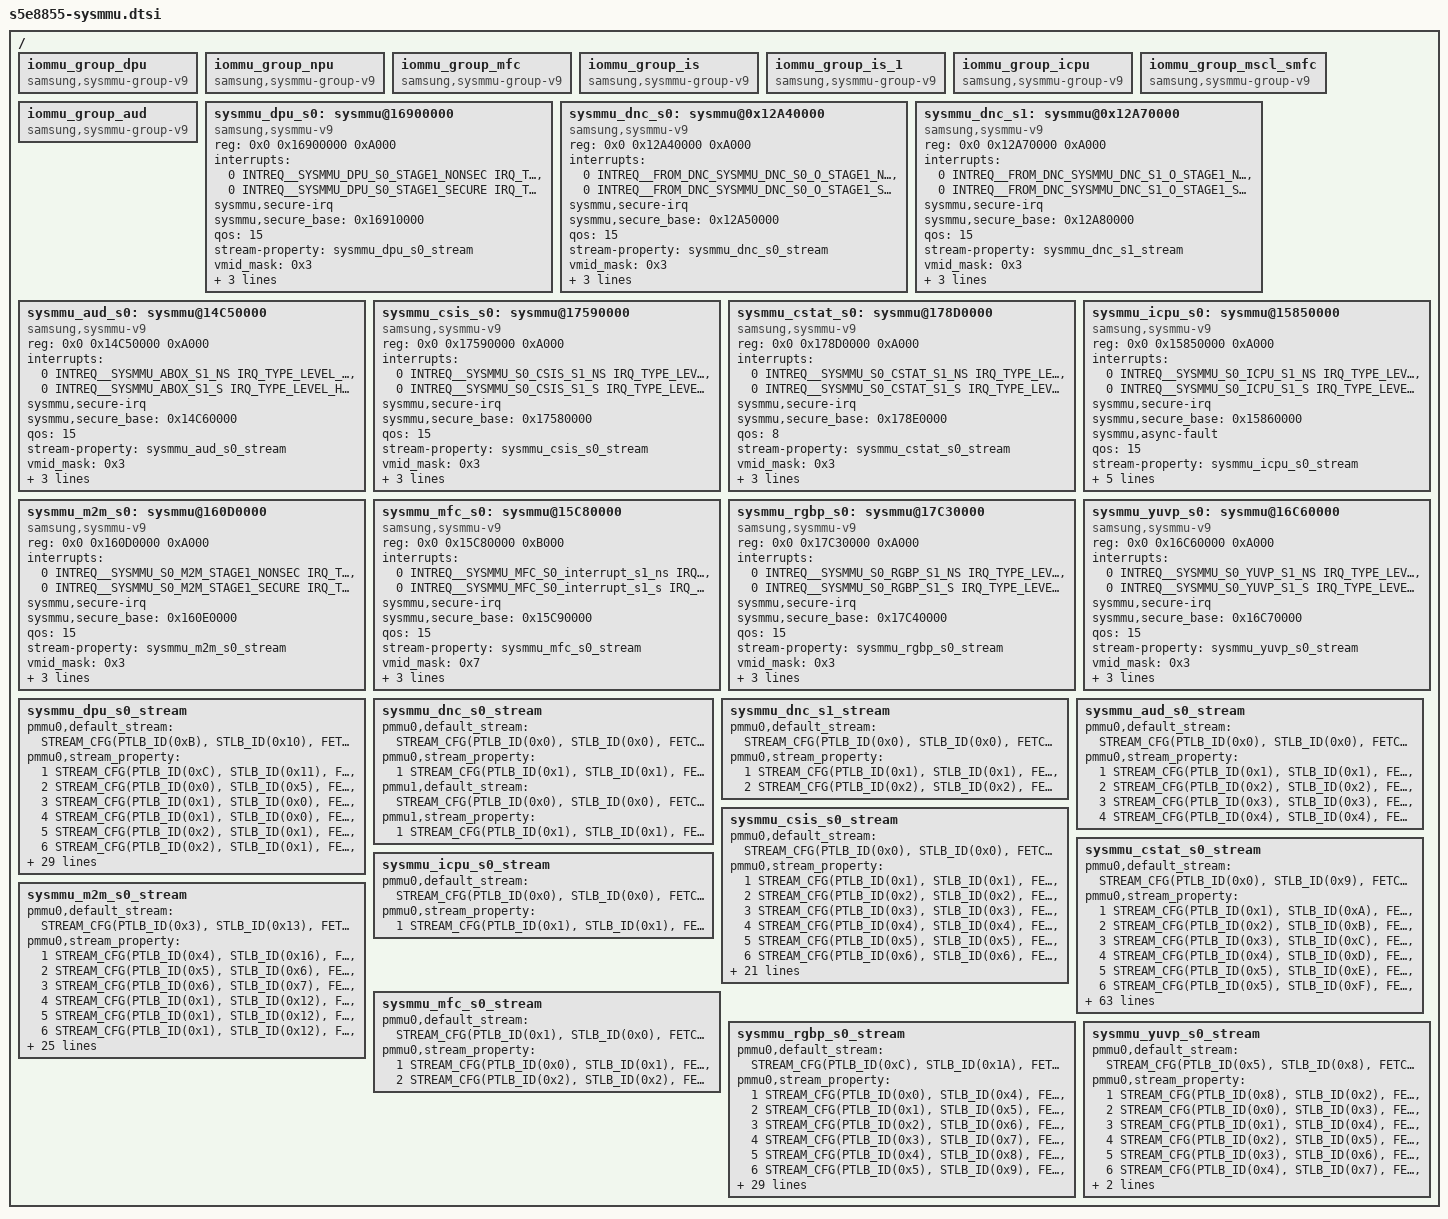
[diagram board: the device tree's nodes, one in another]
// SPDX-License-Identifier: GPL-2.0
/*
 * SAMSUNG S5E8855 SoC device tree source
 *
 * Copyright (c) 2023 Samsung Electronics Co., Ltd.
 *      http://www.samsung.com
 *
 * SAMSUNG S5E8855 SoC device nodes are listed in this file.
 * S5E8855 based board files can include this file and provide
 * values for board specific bindings.
 *
 * This program is free software; you can redistribute it and/or modify
 * it under the terms of the GNU General Public License version 2 as
 * published by the Free Software Foundation.
 */

#include <dt-bindings/interrupt-controller/arm-gic.h>
#include <dt-bindings/soc/samsung,sysmmu-v9.h>

/ {
	iommu_group_dpu: iommu_group_dpu {
		compatible = "samsung,sysmmu-group-v9";
	};

	iommu_group_npu: iommu_group_npu {
		compatible = "samsung,sysmmu-group-v9";
	};

	iommu_group_mfc: iommu_group_mfc {
		compatible = "samsung,sysmmu-group-v9";
	};

	iommu_group_is: iommu_group_is {
		compatible = "samsung,sysmmu-group-v9";
	};

	iommu_group_is_1: iommu_group_is_1 {
		compatible = "samsung,sysmmu-group-v9";
	};

	iommu_group_icpu: iommu_group_icpu {
		compatible = "samsung,sysmmu-group-v9";
	};

	iommu_group_mscl_smfc: iommu_group_mscl_smfc {
		compatible = "samsung,sysmmu-group-v9";
	};

	iommu_group_aud: iommu_group_aud {
		compatible = "samsung,sysmmu-group-v9";
	};

	sysmmu_dpu_s0: sysmmu@16900000 {
		compatible = "samsung,sysmmu-v9";
		reg = <0x0 0x16900000 0xA000>;
		interrupts = <0 INTREQ__SYSMMU_DPU_S0_STAGE1_NONSEC IRQ_TYPE_LEVEL_HIGH>,
				<0 INTREQ__SYSMMU_DPU_S0_STAGE1_SECURE IRQ_TYPE_LEVEL_HIGH>;
		sysmmu,secure-irq;
		sysmmu,secure_base = <0x16910000>;
		qos = <15>;
		#iommu-cells = <0>;
		stream-property = <&sysmmu_dpu_s0_stream>;
		vmid_mask = <0x3>;
		sysmmu,feature-info = <0x1>;
		port-name = "DPU_DMA_TOP";
		power-domains = <&pd_dpu>;
	};

	sysmmu_dnc_s0: sysmmu@0x12A40000 {
		compatible = "samsung,sysmmu-v9";
		reg = <0x0 0x12A40000 0xA000>;
		interrupts = <0 INTREQ__FROM_DNC_SYSMMU_DNC_S0_O_STAGE1_NONSEC IRQ_TYPE_LEVEL_HIGH>,
				<0 INTREQ__FROM_DNC_SYSMMU_DNC_S0_O_STAGE1_SECURE IRQ_TYPE_LEVEL_HIGH>;
		sysmmu,secure-irq;
		sysmmu,secure_base = <0x12A50000>;
		qos = <15>;
		#iommu-cells = <0>;
		stream-property = <&sysmmu_dnc_s0_stream>;
		vmid_mask = <0x3>;
		sysmmu,feature-info = <0x1>;
		power-domains = <&pd_dnc>;
		port-name = "DNC S0";
	};

	sysmmu_dnc_s1: sysmmu@0x12A70000 {
		compatible = "samsung,sysmmu-v9";
		reg = <0x0 0x12A70000 0xA000>;
		interrupts = <0 INTREQ__FROM_DNC_SYSMMU_DNC_S1_O_STAGE1_NONSEC IRQ_TYPE_LEVEL_HIGH>,
				<0 INTREQ__FROM_DNC_SYSMMU_DNC_S1_O_STAGE1_SECURE IRQ_TYPE_LEVEL_HIGH>;
		sysmmu,secure-irq;
		sysmmu,secure_base = <0x12A80000>;
		qos = <15>;
		#iommu-cells = <0>;
		stream-property = <&sysmmu_dnc_s1_stream>;
		vmid_mask = <0x3>;
		sysmmu,feature-info = <0x1>;
		power-domains = <&pd_dnc>;
		port-name = "DNC S1";
	};

	sysmmu_aud_s0: sysmmu@14C50000 {
		compatible = "samsung,sysmmu-v9";
		reg = <0x0 0x14C50000 0xA000>;
		interrupts = <0 INTREQ__SYSMMU_ABOX_S1_NS IRQ_TYPE_LEVEL_HIGH>,
				<0 INTREQ__SYSMMU_ABOX_S1_S IRQ_TYPE_LEVEL_HIGH>;
		sysmmu,secure-irq;
		sysmmu,secure_base = <0x14C60000>;
		qos = <15>;
		#iommu-cells = <0>;
		stream-property = <&sysmmu_aud_s0_stream>;
		vmid_mask = <0x3>;
		sysmmu,feature-info = <0x1>;
		port-name = "ABOX (CA32_0) ABOX (CA32_1) ...";
		power-domains = <&pd_aud>;
	};

	sysmmu_csis_s0: sysmmu@17590000 {
		compatible = "samsung,sysmmu-v9";
		reg = <0x0 0x17590000 0xA000>;
		interrupts = <0 INTREQ__SYSMMU_S0_CSIS_S1_NS IRQ_TYPE_LEVEL_HIGH>,
				<0 INTREQ__SYSMMU_S0_CSIS_S1_S IRQ_TYPE_LEVEL_HIGH>;
		sysmmu,secure-irq;
		sysmmu,secure_base = <0x17580000>;
		qos = <15>;
		#iommu-cells = <0>;
		stream-property = <&sysmmu_csis_s0_stream>;
		vmid_mask = <0x3>;
		sysmmu,feature-info = <0x1>;
		port-name = "CSIS DMA0-3, PDP_M0 ...";
		power-domains = <&pd_csis>;
	};

	sysmmu_cstat_s0: sysmmu@178D0000 {
		compatible = "samsung,sysmmu-v9";
		reg = <0x0 0x178D0000 0xA000>;
		interrupts = <0 INTREQ__SYSMMU_S0_CSTAT_S1_NS IRQ_TYPE_LEVEL_HIGH>,
				<0 INTREQ__SYSMMU_S0_CSTAT_S1_S IRQ_TYPE_LEVEL_HIGH>;
		sysmmu,secure-irq;
		sysmmu,secure_base = <0x178E0000>;
		qos = <8>;
		#iommu-cells = <0>;
		stream-property = <&sysmmu_cstat_s0_stream>;
		vmid_mask = <0x3>;
		sysmmu,feature-info = <0x1>;
		port-name = "CSTAT, BYRP, MCSC ...";
		power-domains = <&pd_cstat>;
	};

	sysmmu_icpu_s0: sysmmu@15850000 {
		compatible = "samsung,sysmmu-v9";
		reg = <0x0 0x15850000 0xA000>;
		interrupts = <0 INTREQ__SYSMMU_S0_ICPU_S1_NS IRQ_TYPE_LEVEL_HIGH>,
				<0 INTREQ__SYSMMU_S0_ICPU_S1_S  IRQ_TYPE_LEVEL_HIGH>;
		sysmmu,secure-irq;
		sysmmu,secure_base = <0x15860000>;
		sysmmu,async-fault;
		qos = <15>;
		#iommu-cells = <0>;
		stream-property = <&sysmmu_icpu_s0_stream>;
		vmid_mask = <0x3>;
		sysmmu,feature-info = <0x1>;
		sysmmu,cacheable-override;
		port-name = "ICPU";
		power-domains = <&pd_icpu>;
	};

	sysmmu_m2m_s0: sysmmu@160D0000 {
		compatible = "samsung,sysmmu-v9";
		reg = <0x0 0x160D0000 0xA000>;
		interrupts = <0 INTREQ__SYSMMU_S0_M2M_STAGE1_NONSEC IRQ_TYPE_LEVEL_HIGH>,
				<0 INTREQ__SYSMMU_S0_M2M_STAGE1_SECURE IRQ_TYPE_LEVEL_HIGH>;
		sysmmu,secure-irq;
		sysmmu,secure_base = <0x160E0000>;
		qos = <15>;
		#iommu-cells = <0>;
		stream-property = <&sysmmu_m2m_s0_stream>;
		vmid_mask = <0x3>;
		sysmmu,feature-info = <0x1>;
		port-name = "M2M, SMFC, GDC ...";
		power-domains = <&pd_m2m>;
	};

	sysmmu_mfc_s0: sysmmu@15C80000 {
		compatible = "samsung,sysmmu-v9";
		reg = <0x0 0x15C80000 0xB000>;
		interrupts = <0 INTREQ__SYSMMU_MFC_S0_interrupt_s1_ns IRQ_TYPE_LEVEL_HIGH>,
				<0 INTREQ__SYSMMU_MFC_S0_interrupt_s1_s IRQ_TYPE_LEVEL_HIGH>;
		sysmmu,secure-irq;
		sysmmu,secure_base = <0x15C90000>;
		qos = <15>;
		#iommu-cells = <0>;
		stream-property = <&sysmmu_mfc_s0_stream>;
		vmid_mask = <0x7>;
		sysmmu,feature-info = <0x1>;
		port-name = "MFC0";
		power-domains = <&pd_mfc>;
	};

	sysmmu_rgbp_s0: sysmmu@17C30000 {
		compatible = "samsung,sysmmu-v9";
		reg = <0x0 0x17C30000 0xA000>;
		interrupts = <0 INTREQ__SYSMMU_S0_RGBP_S1_NS IRQ_TYPE_LEVEL_HIGH>,
				<0 INTREQ__SYSMMU_S0_RGBP_S1_S IRQ_TYPE_LEVEL_HIGH>;
		sysmmu,secure-irq;
		sysmmu,secure_base = <0x17C40000>;
		qos = <15>;
		#iommu-cells = <0>;
		stream-property = <&sysmmu_rgbp_s0_stream>;
		vmid_mask = <0x3>;
		sysmmu,feature-info = <0x1>;
		port-name = "RGBP, MCFP ...";
		power-domains = <&pd_rgbp>;
	};

	sysmmu_yuvp_s0: sysmmu@16C60000 {
		compatible = "samsung,sysmmu-v9";
		reg = <0x0 0x16C60000 0xA000>;
		interrupts = <0 INTREQ__SYSMMU_S0_YUVP_S1_NS IRQ_TYPE_LEVEL_HIGH>,
				<0 INTREQ__SYSMMU_S0_YUVP_S1_S IRQ_TYPE_LEVEL_HIGH>;
		sysmmu,secure-irq;
		sysmmu,secure_base = <0x16C70000>;
		qos = <15>;
		#iommu-cells = <0>;
		stream-property = <&sysmmu_yuvp_s0_stream>;
		vmid_mask = <0x3>;
		sysmmu,feature-info = <0x1>;
		port-name = "YUVP";
		power-domains = <&pd_yuvp>;
	};

	sysmmu_dpu_s0_stream: sysmmu_dpu_s0_stream {
		pmmu0,default_stream =
		<STREAM_CFG(PTLB_ID(0xB), STLB_ID(0x10), FETCH_SIZE(SIZE1), PTLB_EN, STLB_EN)>;
		pmmu0,stream_property =
		<1 STREAM_CFG(PTLB_ID(0xC), STLB_ID(0x11), FETCH_SIZE(SIZE1), PTLB_EN, STLB_EN)
		 STREAM_MATCH_CFG(DIR_READ)
		 STREAM_MATCH_SID_VALUE(0x1A)
		 STREAM_MATCH_SID_MASK(0xFF)>,
		<2 STREAM_CFG(PTLB_ID(0x0), STLB_ID(0x5), FETCH_SIZE(SIZE2), PTLB_EN, STLB_EN)
		 STREAM_MATCH_CFG(DIR_READ)
		 STREAM_MATCH_SID_VALUE(0x0)
		 STREAM_MATCH_SID_MASK(0xFF)>,
		<3 STREAM_CFG(PTLB_ID(0x1), STLB_ID(0x0), FETCH_SIZE(SIZE32), PTLB_DIS, STLB_EN)
		 STREAM_MATCH_CFG(DIR_READ)
		 STREAM_MATCH_SID_VALUE(0x4)
		 STREAM_MATCH_SID_MASK(0xFF)>,
		<4 STREAM_CFG(PTLB_ID(0x1), STLB_ID(0x0), FETCH_SIZE(SIZE32), PTLB_DIS, STLB_EN)
		 STREAM_MATCH_CFG(DIR_READ)
		 STREAM_MATCH_SID_VALUE(0x14)
		 STREAM_MATCH_SID_MASK(0xFF)>,
		<5 STREAM_CFG(PTLB_ID(0x2), STLB_ID(0x1), FETCH_SIZE(SIZE32), PTLB_DIS, STLB_EN)
		 STREAM_MATCH_CFG(DIR_READ)
		 STREAM_MATCH_SID_VALUE(0x5)
		 STREAM_MATCH_SID_MASK(0xFF)>,
		<6 STREAM_CFG(PTLB_ID(0x2), STLB_ID(0x1), FETCH_SIZE(SIZE32), PTLB_DIS, STLB_EN)
		 STREAM_MATCH_CFG(DIR_READ)
		 STREAM_MATCH_SID_VALUE(0x15)
		 STREAM_MATCH_SID_MASK(0xFF)>,
		<7 STREAM_CFG(PTLB_ID(0x3), STLB_ID(0x6), FETCH_SIZE(SIZE2), PTLB_EN, STLB_EN)
		 STREAM_MATCH_CFG(DIR_READ)
		 STREAM_MATCH_SID_VALUE(0x6)
		 STREAM_MATCH_SID_MASK(0xFF)>,
		<8 STREAM_CFG(PTLB_ID(0x4), STLB_ID(0x12), FETCH_SIZE(SIZE1), PTLB_EN, STLB_EN)
		 STREAM_MATCH_CFG(DIR_READ)
		 STREAM_MATCH_SID_VALUE(0x7)
		 STREAM_MATCH_SID_MASK(0xFF)>,
		<9 STREAM_CFG(PTLB_ID(0x5), STLB_ID(0x2), FETCH_SIZE(SIZE16), PTLB_EN, STLB_EN)
		 STREAM_MATCH_CFG(DIR_READ)
		 STREAM_MATCH_SID_VALUE(0x8)
		 STREAM_MATCH_SID_MASK(0xFF)>,
		<10 STREAM_CFG(PTLB_ID(0x5), STLB_ID(0x2), FETCH_SIZE(SIZE16), PTLB_EN, STLB_EN)
		 STREAM_MATCH_CFG(DIR_READ)
		 STREAM_MATCH_SID_VALUE(0x18)
		 STREAM_MATCH_SID_MASK(0xFF)>,
		<11 STREAM_CFG(PTLB_ID(0x6), STLB_ID(0x7), FETCH_SIZE(SIZE2), PTLB_EN, STLB_EN)
		 STREAM_MATCH_CFG(DIR_READ)
		 STREAM_MATCH_SID_VALUE(0xA)
		 STREAM_MATCH_SID_MASK(0xFF)>,
		<12 STREAM_CFG(PTLB_ID(0x7), STLB_ID(0x8), FETCH_SIZE(SIZE2), PTLB_EN, STLB_EN)
		 STREAM_MATCH_CFG(DIR_READ)
		 STREAM_MATCH_SID_VALUE(0xC)
		 STREAM_MATCH_SID_MASK(0xFF)>,
		<13 STREAM_CFG(PTLB_ID(0x7), STLB_ID(0x8), FETCH_SIZE(SIZE2), PTLB_EN, STLB_EN)
		 STREAM_MATCH_CFG(DIR_READ)
		 STREAM_MATCH_SID_VALUE(0x1C)
		 STREAM_MATCH_SID_MASK(0xFF)>,
		<14 STREAM_CFG(PTLB_ID(0x8), STLB_ID(0x9), FETCH_SIZE(SIZE2), PTLB_EN, STLB_EN)
		 STREAM_MATCH_CFG(DIR_READ)
		 STREAM_MATCH_SID_VALUE(0xD)
		 STREAM_MATCH_SID_MASK(0xFF)>,
		<15 STREAM_CFG(PTLB_ID(0x8), STLB_ID(0x9), FETCH_SIZE(SIZE2), PTLB_EN, STLB_EN)
		 STREAM_MATCH_CFG(DIR_READ)
		 STREAM_MATCH_SID_VALUE(0x1D)
		 STREAM_MATCH_SID_MASK(0xFF)>,
		<16 STREAM_CFG(PTLB_ID(0x9), STLB_ID(0x13), FETCH_SIZE(SIZE1), PTLB_EN, STLB_EN)
		 STREAM_MATCH_CFG(DIR_READ)
		 STREAM_MATCH_SID_VALUE(0xE)
		 STREAM_MATCH_SID_MASK(0xFF)>,
		<17 STREAM_CFG(PTLB_ID(0xA), STLB_ID(0x14), FETCH_SIZE(SIZE1), PTLB_EN, STLB_EN)
		 STREAM_MATCH_CFG(DIR_READ)
		 STREAM_MATCH_SID_VALUE(0xF)
		 STREAM_MATCH_SID_MASK(0xFF)>;
		pmmu1,default_stream =
		<STREAM_CFG(PTLB_ID(0x0), STLB_ID(0x19), FETCH_SIZE(SIZE1), PTLB_EN, STLB_EN)>;
		pmmu1,stream_property =
		<1 STREAM_CFG(PTLB_ID(0x1), STLB_ID(0x3), FETCH_SIZE(SIZE16), PTLB_EN, STLB_EN)
		 STREAM_MATCH_CFG(DIR_READ)
		 STREAM_MATCH_SID_VALUE(0x80)
		 STREAM_MATCH_SID_MASK(0xFF)>,
		<2 STREAM_CFG(PTLB_ID(0x1), STLB_ID(0x3), FETCH_SIZE(SIZE16), PTLB_EN, STLB_EN)
		 STREAM_MATCH_CFG(DIR_READ)
		 STREAM_MATCH_SID_VALUE(0x90)
		 STREAM_MATCH_SID_MASK(0xFF)>,
		<3 STREAM_CFG(PTLB_ID(0x2), STLB_ID(0xA), FETCH_SIZE(SIZE2), PTLB_EN, STLB_EN)
		 STREAM_MATCH_CFG(DIR_READ)
		 STREAM_MATCH_SID_VALUE(0x82)
		 STREAM_MATCH_SID_MASK(0xFF)>,
		<4 STREAM_CFG(PTLB_ID(0x3), STLB_ID(0xB), FETCH_SIZE(SIZE2), PTLB_EN, STLB_EN)
		 STREAM_MATCH_CFG(DIR_READ)
		 STREAM_MATCH_SID_VALUE(0x84)
		 STREAM_MATCH_SID_MASK(0xFF)>,
		<5 STREAM_CFG(PTLB_ID(0x4), STLB_ID(0xC), FETCH_SIZE(SIZE1), PTLB_EN, STLB_EN)
		 STREAM_MATCH_CFG(DIR_READ)
		 STREAM_MATCH_SID_VALUE(0x85)
		 STREAM_MATCH_SID_MASK(0xFF)>,
		<6 STREAM_CFG(PTLB_ID(0x5), STLB_ID(0xD), FETCH_SIZE(SIZE1), PTLB_EN, STLB_EN)
		 STREAM_MATCH_CFG(DIR_READ)
		 STREAM_MATCH_SID_VALUE(0x88)
		 STREAM_MATCH_SID_MASK(0xFF)>,
		<7 STREAM_CFG(PTLB_ID(0x6), STLB_ID(0x4), FETCH_SIZE(SIZE16), PTLB_EN, STLB_EN)
		 STREAM_MATCH_CFG(DIR_READ)
		 STREAM_MATCH_SID_VALUE(0x8C)
		 STREAM_MATCH_SID_MASK(0xFF)>,
		<8 STREAM_CFG(PTLB_ID(0x7), STLB_ID(0x4), FETCH_SIZE(SIZE16), PTLB_EN, STLB_EN)
		 STREAM_MATCH_CFG(DIR_READ)
		 STREAM_MATCH_SID_VALUE(0x9C)
		 STREAM_MATCH_SID_MASK(0xFF)>,
		<9 STREAM_CFG(PTLB_ID(0x7), STLB_ID(0xE), FETCH_SIZE(SIZE2), PTLB_EN, STLB_EN)
		 STREAM_MATCH_CFG(DIR_READ)
		 STREAM_MATCH_SID_VALUE(0x8D)
		 STREAM_MATCH_SID_MASK(0xFF)>,
		<10 STREAM_CFG(PTLB_ID(0x8), STLB_ID(0xE), FETCH_SIZE(SIZE2), PTLB_EN, STLB_EN)
		 STREAM_MATCH_CFG(DIR_READ)
		 STREAM_MATCH_SID_VALUE(0x9D)
		 STREAM_MATCH_SID_MASK(0xFF)>,
		<11 STREAM_CFG(PTLB_ID(0x8), STLB_ID(0xF), FETCH_SIZE(SIZE1), PTLB_EN, STLB_EN)
		 STREAM_MATCH_CFG(DIR_READ)
		 STREAM_MATCH_SID_VALUE(0x8E)
		 STREAM_MATCH_SID_MASK(0xFF)>,
		<12 STREAM_CFG(PTLB_ID(0x9), STLB_ID(0x15), FETCH_SIZE(SIZE1), PTLB_EN, STLB_EN)
		 STREAM_MATCH_CFG(DIR_READ)
		 STREAM_MATCH_SID_VALUE(0x8F)
		 STREAM_MATCH_SID_MASK(0xFF)>,
		<13 STREAM_CFG(PTLB_ID(0xA), STLB_ID(0x16), FETCH_SIZE(SIZE1), PTLB_EN, STLB_EN)
		 STREAM_MATCH_CFG(DIR_WRITE)
		 STREAM_MATCH_SID_VALUE(0x80)
		 STREAM_MATCH_SID_MASK(0xFF)>,
		<14 STREAM_CFG(PTLB_ID(0xB), STLB_ID(0x17), FETCH_SIZE(SIZE1), PTLB_EN, STLB_EN)
		 STREAM_MATCH_CFG(DIR_WRITE)
		 STREAM_MATCH_SID_VALUE(0x81)
		 STREAM_MATCH_SID_MASK(0xFF)>,
		<15 STREAM_CFG(PTLB_ID(0xC), STLB_ID(0x18), FETCH_SIZE(SIZE1), PTLB_EN, STLB_DIS)
		 STREAM_MATCH_CFG(DIR_WRITE)
		 STREAM_MATCH_SID_VALUE(0x88)
		 STREAM_MATCH_SID_MASK(0xFF)>;
	};

	sysmmu_dnc_s0_stream: sysmmu_dnc_s0_stream {
		pmmu0,default_stream =
		<STREAM_CFG(PTLB_ID(0x0), STLB_ID(0x0), FETCH_SIZE(SIZE8), PTLB_EN, STLB_EN)>;
		pmmu0,stream_property =
		<1 STREAM_CFG(PTLB_ID(0x1), STLB_ID(0x1), FETCH_SIZE(SIZE1), PTLB_DIS, STLB_DIS)
		 STREAM_MATCH_CFG(DIR_RW)
		 STREAM_MATCH_SID_VALUE(0x20)
		 STREAM_MATCH_SID_MASK(0xA0)>;
		pmmu1,default_stream =
		<STREAM_CFG(PTLB_ID(0x0), STLB_ID(0x0), FETCH_SIZE(SIZE8), PTLB_EN, STLB_EN)>;
		pmmu1,stream_property =
		<1 STREAM_CFG(PTLB_ID(0x1), STLB_ID(0x1), FETCH_SIZE(SIZE1), PTLB_DIS, STLB_DIS)
		 STREAM_MATCH_CFG(DIR_RW)
		 STREAM_MATCH_SID_VALUE(0xA0)
		 STREAM_MATCH_SID_MASK(0xA0)>;
	};

	sysmmu_dnc_s1_stream: sysmmu_dnc_s1_stream {
		pmmu0,default_stream =
		<STREAM_CFG(PTLB_ID(0x0), STLB_ID(0x0), FETCH_SIZE(SIZE1), PTLB_DIS, STLB_DIS)>;
		pmmu0,stream_property =
		<1 STREAM_CFG(PTLB_ID(0x1), STLB_ID(0x1), FETCH_SIZE(SIZE1), PTLB_DIS, STLB_EN)
		 STREAM_MATCH_CFG(DIR_READ)
		 STREAM_MATCH_SID_VALUE(0x101)
		 STREAM_MATCH_SID_MASK(0x1FF)>,
		<2 STREAM_CFG(PTLB_ID(0x2), STLB_ID(0x2), FETCH_SIZE(SIZE1), PTLB_DIS, STLB_DIS)
		 STREAM_MATCH_CFG(DIR_WRITE)
		 STREAM_MATCH_SID_VALUE(0x102)
		 STREAM_MATCH_SID_MASK(0x1FF)>;
	};

	sysmmu_aud_s0_stream: sysmmu_aud_s0_stream {
		pmmu0,default_stream =
		<STREAM_CFG(PTLB_ID(0x0), STLB_ID(0x0), FETCH_SIZE(SIZE1), PTLB_DIS, STLB_DIS)>;
		pmmu0,stream_property =
		<1 STREAM_CFG(PTLB_ID(0x1), STLB_ID(0x1), FETCH_SIZE(SIZE1), PTLB_DIS, STLB_DIS)
		 STREAM_MATCH_CFG(DIR_RW)
		 STREAM_MATCH_SID_VALUE(0x1)
		 STREAM_MATCH_SID_MASK(0xF)>,
		<2 STREAM_CFG(PTLB_ID(0x2), STLB_ID(0x2), FETCH_SIZE(SIZE1), PTLB_DIS, STLB_EN)
		 STREAM_MATCH_CFG(DIR_RW)
		 STREAM_MATCH_SID_VALUE(0x3)
		 STREAM_MATCH_SID_MASK(0xF)>,
		<3 STREAM_CFG(PTLB_ID(0x3), STLB_ID(0x3), FETCH_SIZE(SIZE1), PTLB_DIS, STLB_DIS)
		 STREAM_MATCH_CFG(DIR_WRITE)
		 STREAM_MATCH_SID_VALUE(0x4)
		 STREAM_MATCH_SID_MASK(0xF)>,
		<4 STREAM_CFG(PTLB_ID(0x4), STLB_ID(0x4), FETCH_SIZE(SIZE1), PTLB_DIS, STLB_DIS)
		 STREAM_MATCH_CFG(DIR_WRITE)
		 STREAM_MATCH_SID_VALUE(0x5)
		 STREAM_MATCH_SID_MASK(0xF)>;
	};

	sysmmu_csis_s0_stream: sysmmu_csis_s0_stream {
		pmmu0,default_stream =
		<STREAM_CFG(PTLB_ID(0x0), STLB_ID(0x0), FETCH_SIZE(SIZE1), PTLB_EN, STLB_EN)>;
		pmmu0,stream_property =
		<1 STREAM_CFG(PTLB_ID(0x1), STLB_ID(0x1), FETCH_SIZE(SIZE1), PTLB_EN, STLB_EN)
		 STREAM_MATCH_CFG(DIR_WRITE)
		 STREAM_MATCH_SID_VALUE(0x1)
		 STREAM_MATCH_SID_MASK(0xF)>,
		<2 STREAM_CFG(PTLB_ID(0x2), STLB_ID(0x2), FETCH_SIZE(SIZE1), PTLB_EN, STLB_EN)
		 STREAM_MATCH_CFG(DIR_WRITE)
		 STREAM_MATCH_SID_VALUE(0x2)
		 STREAM_MATCH_SID_MASK(0xF)>,
		<3 STREAM_CFG(PTLB_ID(0x3), STLB_ID(0x3), FETCH_SIZE(SIZE1), PTLB_EN, STLB_EN)
		 STREAM_MATCH_CFG(DIR_WRITE)
		 STREAM_MATCH_SID_VALUE(0x4)
		 STREAM_MATCH_SID_MASK(0xF)>,
		<4 STREAM_CFG(PTLB_ID(0x4), STLB_ID(0x4), FETCH_SIZE(SIZE1), PTLB_EN, STLB_EN)
		 STREAM_MATCH_CFG(DIR_WRITE)
		 STREAM_MATCH_SID_VALUE(0x6)
		 STREAM_MATCH_SID_MASK(0xF)>,
		<5 STREAM_CFG(PTLB_ID(0x5), STLB_ID(0x5), FETCH_SIZE(SIZE1), PTLB_EN, STLB_EN)
		 STREAM_MATCH_CFG(DIR_WRITE)
		 STREAM_MATCH_SID_VALUE(0x80)
		 STREAM_MATCH_SID_MASK(0xFF)>,
		<6 STREAM_CFG(PTLB_ID(0x6), STLB_ID(0x6), FETCH_SIZE(SIZE1), PTLB_EN, STLB_EN)
		 STREAM_MATCH_CFG(DIR_WRITE)
		 STREAM_MATCH_SID_VALUE(0x81)
		 STREAM_MATCH_SID_MASK(0xFF)>,
		<7 STREAM_CFG(PTLB_ID(0x7), STLB_ID(0x7), FETCH_SIZE(SIZE1), PTLB_EN, STLB_EN)
		 STREAM_MATCH_CFG(DIR_WRITE)
		 STREAM_MATCH_SID_VALUE(0x82)
		 STREAM_MATCH_SID_MASK(0xFF)>,
		<8 STREAM_CFG(PTLB_ID(0x8), STLB_ID(0x8), FETCH_SIZE(SIZE1), PTLB_EN, STLB_EN)
		 STREAM_MATCH_CFG(DIR_WRITE)
		 STREAM_MATCH_SID_VALUE(0x84)
		 STREAM_MATCH_SID_MASK(0xFF)>,
		<9 STREAM_CFG(PTLB_ID(0x9), STLB_ID(0x9), FETCH_SIZE(SIZE1), PTLB_EN, STLB_EN)
		 STREAM_MATCH_CFG(DIR_WRITE)
		 STREAM_MATCH_SID_VALUE(0x86)
		 STREAM_MATCH_SID_MASK(0xFF)>;
		pmmu1,default_stream =
		<STREAM_CFG(PTLB_ID(0x0), STLB_ID(0xA), FETCH_SIZE(SIZE1), PTLB_EN, STLB_EN)>;
		pmmu1,stream_property =
		<1 STREAM_CFG(PTLB_ID(0x1), STLB_ID(0xB), FETCH_SIZE(SIZE1), PTLB_EN, STLB_EN)
		 STREAM_MATCH_CFG(DIR_WRITE)
		 STREAM_MATCH_SID_VALUE(0x1)
		 STREAM_MATCH_SID_MASK(0x3FF)>,
		<2 STREAM_CFG(PTLB_ID(0x2), STLB_ID(0xC), FETCH_SIZE(SIZE1), PTLB_EN, STLB_EN)
		 STREAM_MATCH_CFG(DIR_WRITE)
		 STREAM_MATCH_SID_VALUE(0x2)
		 STREAM_MATCH_SID_MASK(0x3FF)>,
		<3 STREAM_CFG(PTLB_ID(0x3), STLB_ID(0xD), FETCH_SIZE(SIZE1), PTLB_EN, STLB_EN)
		 STREAM_MATCH_CFG(DIR_WRITE)
		 STREAM_MATCH_SID_VALUE(0x4)
		 STREAM_MATCH_SID_MASK(0x3FF)>,
		<4 STREAM_CFG(PTLB_ID(0x4), STLB_ID(0xE), FETCH_SIZE(SIZE1), PTLB_EN, STLB_EN)
		 STREAM_MATCH_CFG(DIR_WRITE)
		 STREAM_MATCH_SID_VALUE(0x6)
		 STREAM_MATCH_SID_MASK(0x3FF)>,
		<5 STREAM_CFG(PTLB_ID(0x5), STLB_ID(0xF), FETCH_SIZE(SIZE1), PTLB_EN, STLB_EN)
		 STREAM_MATCH_CFG(DIR_WRITE)
		 STREAM_MATCH_SID_VALUE(0x80)
		 STREAM_MATCH_SID_MASK(0x3FF)>,
		<6 STREAM_CFG(PTLB_ID(0x6), STLB_ID(0x10), FETCH_SIZE(SIZE1), PTLB_EN, STLB_EN)
		 STREAM_MATCH_CFG(DIR_WRITE)
		 STREAM_MATCH_SID_VALUE(0x81)
		 STREAM_MATCH_SID_MASK(0x3FF)>,
		<7 STREAM_CFG(PTLB_ID(0x7), STLB_ID(0x11), FETCH_SIZE(SIZE1), PTLB_EN, STLB_EN)
		 STREAM_MATCH_CFG(DIR_WRITE)
		 STREAM_MATCH_SID_VALUE(0x82)
		 STREAM_MATCH_SID_MASK(0x3FF)>,
		<8 STREAM_CFG(PTLB_ID(0x8), STLB_ID(0x12), FETCH_SIZE(SIZE1), PTLB_EN, STLB_EN)
		 STREAM_MATCH_CFG(DIR_WRITE)
		 STREAM_MATCH_SID_VALUE(0x84)
		 STREAM_MATCH_SID_MASK(0x3FF)>,
		<9 STREAM_CFG(PTLB_ID(0x9), STLB_ID(0x13), FETCH_SIZE(SIZE1), PTLB_EN, STLB_EN)
		 STREAM_MATCH_CFG(DIR_WRITE)
		 STREAM_MATCH_SID_VALUE(0x86)
		 STREAM_MATCH_SID_MASK(0x3FF)>,
		<10 STREAM_CFG(PTLB_ID(0xA), STLB_ID(0x14), FETCH_SIZE(SIZE1), PTLB_EN, STLB_EN)
		 STREAM_MATCH_CFG(DIR_READ)
		 STREAM_MATCH_SID_VALUE(0x100)
		 STREAM_MATCH_SID_MASK(0x3FF)>,
		<11 STREAM_CFG(PTLB_ID(0xB), STLB_ID(0x15), FETCH_SIZE(SIZE1), PTLB_EN, STLB_EN)
		 STREAM_MATCH_CFG(DIR_WRITE)
		 STREAM_MATCH_SID_VALUE(0x100)
		 STREAM_MATCH_SID_MASK(0x3FF)>,
		<12 STREAM_CFG(PTLB_ID(0xC), STLB_ID(0x16), FETCH_SIZE(SIZE1), PTLB_EN, STLB_EN)
		 STREAM_MATCH_CFG(DIR_WRITE)
		 STREAM_MATCH_SID_VALUE(0x108)
		 STREAM_MATCH_SID_MASK(0x3FF)>,
		<13 STREAM_CFG(PTLB_ID(0xD), STLB_ID(0x17), FETCH_SIZE(SIZE1), PTLB_EN, STLB_EN)
		 STREAM_MATCH_CFG(DIR_WRITE)
		 STREAM_MATCH_SID_VALUE(0x110)
		 STREAM_MATCH_SID_MASK(0x3FF)>,
		<14 STREAM_CFG(PTLB_ID(0xF), STLB_ID(0x19), FETCH_SIZE(SIZE1), PTLB_EN, STLB_DIS)
		 STREAM_MATCH_CFG(DIR_WRITE)
		 STREAM_MATCH_SID_VALUE(0x180)
		 STREAM_MATCH_SID_MASK(0x3FF)>,
		<15 STREAM_CFG(PTLB_ID(0xE), STLB_ID(0x18), FETCH_SIZE(SIZE1), PTLB_EN, STLB_DIS)
		 STREAM_MATCH_CFG(DIR_WRITE)
		 STREAM_MATCH_SID_VALUE(0x200)
		 STREAM_MATCH_SID_MASK(0x3FF)>;
	};

	sysmmu_cstat_s0_stream: sysmmu_cstat_s0_stream {
		pmmu0,default_stream =
		<STREAM_CFG(PTLB_ID(0x0), STLB_ID(0x9), FETCH_SIZE(SIZE1), PTLB_DIS, STLB_EN)>;
		pmmu0,stream_property =
		<1 STREAM_CFG(PTLB_ID(0x1), STLB_ID(0xA), FETCH_SIZE(SIZE1), PTLB_DIS, STLB_EN)
		 STREAM_MATCH_CFG(DIR_WRITE)
		 STREAM_MATCH_SID_VALUE(0x8)
		 STREAM_MATCH_SID_MASK(0x7FF)>,
		<2 STREAM_CFG(PTLB_ID(0x2), STLB_ID(0xB), FETCH_SIZE(SIZE1), PTLB_DIS, STLB_EN)
		 STREAM_MATCH_CFG(DIR_WRITE)
		 STREAM_MATCH_SID_VALUE(0x10)
		 STREAM_MATCH_SID_MASK(0x7FF)>,
		<3 STREAM_CFG(PTLB_ID(0x3), STLB_ID(0xC), FETCH_SIZE(SIZE1), PTLB_EN, STLB_EN)
		 STREAM_MATCH_CFG(DIR_READ)
		 STREAM_MATCH_SID_VALUE(0x0)
		 STREAM_MATCH_SID_MASK(0x7FF)>,
		<4 STREAM_CFG(PTLB_ID(0x4), STLB_ID(0xD), FETCH_SIZE(SIZE1), PTLB_EN, STLB_EN)
		 STREAM_MATCH_CFG(DIR_READ)
		 STREAM_MATCH_SID_VALUE(0x1)
		 STREAM_MATCH_SID_MASK(0x7FF)>,
		<5 STREAM_CFG(PTLB_ID(0x5), STLB_ID(0xE), FETCH_SIZE(SIZE1), PTLB_DIS, STLB_EN)
		 STREAM_MATCH_CFG(DIR_WRITE)
		 STREAM_MATCH_SID_VALUE(0x80)
		 STREAM_MATCH_SID_MASK(0x7FF)>,
		<6 STREAM_CFG(PTLB_ID(0x5), STLB_ID(0xF), FETCH_SIZE(SIZE1), PTLB_DIS, STLB_EN)
		 STREAM_MATCH_CFG(DIR_WRITE)
		 STREAM_MATCH_SID_VALUE(0x88)
		 STREAM_MATCH_SID_MASK(0x7FF)>,
		<7 STREAM_CFG(PTLB_ID(0x5), STLB_ID(0x10), FETCH_SIZE(SIZE1), PTLB_DIS, STLB_EN)
		 STREAM_MATCH_CFG(DIR_WRITE)
		 STREAM_MATCH_SID_VALUE(0x90)
		 STREAM_MATCH_SID_MASK(0x7FF)>,
		<8 STREAM_CFG(PTLB_ID(0x6), STLB_ID(0x11), FETCH_SIZE(SIZE1), PTLB_EN, STLB_EN)
		 STREAM_MATCH_CFG(DIR_READ)
		 STREAM_MATCH_SID_VALUE(0x80)
		 STREAM_MATCH_SID_MASK(0x7FF)>,
		<9 STREAM_CFG(PTLB_ID(0x7), STLB_ID(0x12), FETCH_SIZE(SIZE1), PTLB_DIS, STLB_EN)
		 STREAM_MATCH_CFG(DIR_WRITE)
		 STREAM_MATCH_SID_VALUE(0x100)
		 STREAM_MATCH_SID_MASK(0x7FF)>,
		<10 STREAM_CFG(PTLB_ID(0x7), STLB_ID(0x13), FETCH_SIZE(SIZE1), PTLB_DIS, STLB_EN)
		 STREAM_MATCH_CFG(DIR_WRITE)
		 STREAM_MATCH_SID_VALUE(0x108)
		 STREAM_MATCH_SID_MASK(0x7FF)>,
		<11 STREAM_CFG(PTLB_ID(0x7), STLB_ID(0x14), FETCH_SIZE(SIZE1), PTLB_DIS, STLB_EN)
		 STREAM_MATCH_CFG(DIR_WRITE)
		 STREAM_MATCH_SID_VALUE(0x110)
		 STREAM_MATCH_SID_MASK(0x7FF)>,
		<12 STREAM_CFG(PTLB_ID(0x8), STLB_ID(0x15), FETCH_SIZE(SIZE1), PTLB_EN, STLB_EN)
		 STREAM_MATCH_CFG(DIR_READ)
		 STREAM_MATCH_SID_VALUE(0x100)
		 STREAM_MATCH_SID_MASK(0x7FF)>,
		<13 STREAM_CFG(PTLB_ID(0x9), STLB_ID(0x16), FETCH_SIZE(SIZE1), PTLB_DIS, STLB_EN)
		 STREAM_MATCH_CFG(DIR_WRITE)
		 STREAM_MATCH_SID_VALUE(0x180)
		 STREAM_MATCH_SID_MASK(0x7FF)>,
		<14 STREAM_CFG(PTLB_ID(0x9), STLB_ID(0x17), FETCH_SIZE(SIZE1), PTLB_DIS, STLB_EN)
		 STREAM_MATCH_CFG(DIR_WRITE)
		 STREAM_MATCH_SID_VALUE(0x188)
		 STREAM_MATCH_SID_MASK(0x7FF)>,
		<15 STREAM_CFG(PTLB_ID(0x9), STLB_ID(0x18), FETCH_SIZE(SIZE1), PTLB_DIS, STLB_EN)
		 STREAM_MATCH_CFG(DIR_WRITE)
		 STREAM_MATCH_SID_VALUE(0x190)
		 STREAM_MATCH_SID_MASK(0x7FF)>,
		<16 STREAM_CFG(PTLB_ID(0xA), STLB_ID(0x19), FETCH_SIZE(SIZE1), PTLB_DIS, STLB_EN)
		 STREAM_MATCH_CFG(DIR_WRITE)
		 STREAM_MATCH_SID_VALUE(0x200)
		 STREAM_MATCH_SID_MASK(0x7FF)>,
		<17 STREAM_CFG(PTLB_ID(0xA), STLB_ID(0x1A), FETCH_SIZE(SIZE1), PTLB_DIS, STLB_EN)
		 STREAM_MATCH_CFG(DIR_WRITE)
		 STREAM_MATCH_SID_VALUE(0x208)
		 STREAM_MATCH_SID_MASK(0x7FF)>,
		<18 STREAM_CFG(PTLB_ID(0xA), STLB_ID(0x1B), FETCH_SIZE(SIZE1), PTLB_DIS, STLB_EN)
		 STREAM_MATCH_CFG(DIR_WRITE)
		 STREAM_MATCH_SID_VALUE(0x210)
		 STREAM_MATCH_SID_MASK(0x7FF)>,
		<19 STREAM_CFG(PTLB_ID(0x12), STLB_ID(0x3B), FETCH_SIZE(SIZE1), PTLB_DIS, STLB_DIS)
		 STREAM_MATCH_CFG(DIR_READ)
		 STREAM_MATCH_SID_VALUE(0x200)
		 STREAM_MATCH_SID_MASK(0x7FF)>,
		<20 STREAM_CFG(PTLB_ID(0xB), STLB_ID(0x1C), FETCH_SIZE(SIZE1), PTLB_DIS, STLB_EN)
		 STREAM_MATCH_CFG(DIR_WRITE)
		 STREAM_MATCH_SID_VALUE(0x280)
		 STREAM_MATCH_SID_MASK(0x7FF)>,
		<21 STREAM_CFG(PTLB_ID(0xB), STLB_ID(0x1D), FETCH_SIZE(SIZE1), PTLB_DIS, STLB_EN)
		 STREAM_MATCH_CFG(DIR_WRITE)
		 STREAM_MATCH_SID_VALUE(0x288)
		 STREAM_MATCH_SID_MASK(0x7FF)>,
		<22 STREAM_CFG(PTLB_ID(0xB), STLB_ID(0x1E), FETCH_SIZE(SIZE1), PTLB_DIS, STLB_EN)
		 STREAM_MATCH_CFG(DIR_WRITE)
		 STREAM_MATCH_SID_VALUE(0x290)
		 STREAM_MATCH_SID_MASK(0x7FF)>,
		<23 STREAM_CFG(PTLB_ID(0x13), STLB_ID(0x3C), FETCH_SIZE(SIZE1), PTLB_DIS, STLB_DIS)
		 STREAM_MATCH_CFG(DIR_READ)
		 STREAM_MATCH_SID_VALUE(0x280)
		 STREAM_MATCH_SID_MASK(0x7FF)>,
		<24 STREAM_CFG(PTLB_ID(0xC), STLB_ID(0x1F), FETCH_SIZE(SIZE1), PTLB_DIS, STLB_EN)
		 STREAM_MATCH_CFG(DIR_WRITE)
		 STREAM_MATCH_SID_VALUE(0x300)
		 STREAM_MATCH_SID_MASK(0x7FF)>,
		<25 STREAM_CFG(PTLB_ID(0xC), STLB_ID(0x20), FETCH_SIZE(SIZE1), PTLB_DIS, STLB_EN)
		 STREAM_MATCH_CFG(DIR_WRITE)
		 STREAM_MATCH_SID_VALUE(0x308)
		 STREAM_MATCH_SID_MASK(0x7FF)>,
		<26 STREAM_CFG(PTLB_ID(0xC), STLB_ID(0x21), FETCH_SIZE(SIZE1), PTLB_DIS, STLB_EN)
		 STREAM_MATCH_CFG(DIR_WRITE)
		 STREAM_MATCH_SID_VALUE(0x310)
		 STREAM_MATCH_SID_MASK(0x7FF)>,
		<27 STREAM_CFG(PTLB_ID(0x14), STLB_ID(0x3D), FETCH_SIZE(SIZE1), PTLB_DIS, STLB_DIS)
		 STREAM_MATCH_CFG(DIR_READ)
		 STREAM_MATCH_SID_VALUE(0x300)
		 STREAM_MATCH_SID_MASK(0x7FF)>,
		<28 STREAM_CFG(PTLB_ID(0xD), STLB_ID(0x22), FETCH_SIZE(SIZE1), PTLB_DIS, STLB_EN)
		 STREAM_MATCH_CFG(DIR_WRITE)
		 STREAM_MATCH_SID_VALUE(0x380)
		 STREAM_MATCH_SID_MASK(0x7FF)>,
		<29 STREAM_CFG(PTLB_ID(0xD), STLB_ID(0x23), FETCH_SIZE(SIZE1), PTLB_DIS, STLB_EN)
		 STREAM_MATCH_CFG(DIR_WRITE)
		 STREAM_MATCH_SID_VALUE(0x388)
		 STREAM_MATCH_SID_MASK(0x7FF)>,
		<30 STREAM_CFG(PTLB_ID(0xD), STLB_ID(0x24), FETCH_SIZE(SIZE1), PTLB_DIS, STLB_EN)
		 STREAM_MATCH_CFG(DIR_WRITE)
		 STREAM_MATCH_SID_VALUE(0x390)
		 STREAM_MATCH_SID_MASK(0x7FF)>,
		<31 STREAM_CFG(PTLB_ID(0xE), STLB_ID(0x25), FETCH_SIZE(SIZE1), PTLB_DIS, STLB_EN)
		 STREAM_MATCH_CFG(DIR_WRITE)
		 STREAM_MATCH_SID_VALUE(0x400)
		 STREAM_MATCH_SID_MASK(0x7FF)>,
		<32 STREAM_CFG(PTLB_ID(0xE), STLB_ID(0x26), FETCH_SIZE(SIZE1), PTLB_DIS, STLB_EN)
		 STREAM_MATCH_CFG(DIR_WRITE)
		 STREAM_MATCH_SID_VALUE(0x408)
		 STREAM_MATCH_SID_MASK(0x7FF)>,
		<33 STREAM_CFG(PTLB_ID(0xE), STLB_ID(0x27), FETCH_SIZE(SIZE1), PTLB_DIS, STLB_EN)
		 STREAM_MATCH_CFG(DIR_WRITE)
		 STREAM_MATCH_SID_VALUE(0x410)
		 STREAM_MATCH_SID_MASK(0x7FF)>,
		<34 STREAM_CFG(PTLB_ID(0xF), STLB_ID(0x28), FETCH_SIZE(SIZE1), PTLB_DIS, STLB_EN)
		 STREAM_MATCH_CFG(DIR_WRITE)
		 STREAM_MATCH_SID_VALUE(0x480)
		 STREAM_MATCH_SID_MASK(0x7FF)>,
		<35 STREAM_CFG(PTLB_ID(0xF), STLB_ID(0x29), FETCH_SIZE(SIZE1), PTLB_DIS, STLB_EN)
		 STREAM_MATCH_CFG(DIR_WRITE)
		 STREAM_MATCH_SID_VALUE(0x482)
		 STREAM_MATCH_SID_MASK(0x7FF)>,
		<36 STREAM_CFG(PTLB_ID(0xF), STLB_ID(0x2A), FETCH_SIZE(SIZE1), PTLB_DIS, STLB_EN)
		 STREAM_MATCH_CFG(DIR_WRITE)
		 STREAM_MATCH_SID_VALUE(0x484)
		 STREAM_MATCH_SID_MASK(0x7FF)>,
		<37 STREAM_CFG(PTLB_ID(0x10), STLB_ID(0x2B), FETCH_SIZE(SIZE1), PTLB_DIS, STLB_EN)
		 STREAM_MATCH_CFG(DIR_WRITE)
		 STREAM_MATCH_SID_VALUE(0x488)
		 STREAM_MATCH_SID_MASK(0x7FF)>,
		<38 STREAM_CFG(PTLB_ID(0x10), STLB_ID(0x2C), FETCH_SIZE(SIZE1), PTLB_DIS, STLB_EN)
		 STREAM_MATCH_CFG(DIR_WRITE)
		 STREAM_MATCH_SID_VALUE(0x48A)
		 STREAM_MATCH_SID_MASK(0x7FF)>,
		<39 STREAM_CFG(PTLB_ID(0x10), STLB_ID(0x2D), FETCH_SIZE(SIZE1), PTLB_DIS, STLB_EN)
		 STREAM_MATCH_CFG(DIR_WRITE)
		 STREAM_MATCH_SID_VALUE(0x48C)
		 STREAM_MATCH_SID_MASK(0x7FF)>,
		<40 STREAM_CFG(PTLB_ID(0x11), STLB_ID(0x2E), FETCH_SIZE(SIZE1), PTLB_DIS, STLB_EN)
		 STREAM_MATCH_CFG(DIR_WRITE)
		 STREAM_MATCH_SID_VALUE(0x490)
		 STREAM_MATCH_SID_MASK(0x7FF)>,
		<41 STREAM_CFG(PTLB_ID(0x11), STLB_ID(0x2F), FETCH_SIZE(SIZE1), PTLB_DIS, STLB_EN)
		 STREAM_MATCH_CFG(DIR_WRITE)
		 STREAM_MATCH_SID_VALUE(0x492)
		 STREAM_MATCH_SID_MASK(0x7FF)>,
		<42 STREAM_CFG(PTLB_ID(0x11), STLB_ID(0x30), FETCH_SIZE(SIZE1), PTLB_DIS, STLB_EN)
		 STREAM_MATCH_CFG(DIR_WRITE)
		 STREAM_MATCH_SID_VALUE(0x494)
		 STREAM_MATCH_SID_MASK(0x7FF)>,
		<43 STREAM_CFG(PTLB_ID(0x15), STLB_ID(0x3F), FETCH_SIZE(SIZE1), PTLB_DIS, STLB_DIS)
		 STREAM_MATCH_CFG(DIR_WRITE)
		 STREAM_MATCH_SID_VALUE(0x500)
		 STREAM_MATCH_SID_MASK(0x7FF)>,
		<44 STREAM_CFG(PTLB_ID(0x16), STLB_ID(0x40), FETCH_SIZE(SIZE1), PTLB_DIS, STLB_DIS)
		 STREAM_MATCH_CFG(DIR_WRITE)
		 STREAM_MATCH_SID_VALUE(0x580)
		 STREAM_MATCH_SID_MASK(0x7FF)>;
		pmmu1,default_stream =
		<STREAM_CFG(PTLB_ID(0x0), STLB_ID(0x31), FETCH_SIZE(SIZE1), PTLB_EN, STLB_EN)>;
		pmmu1,stream_property =
		<1 STREAM_CFG(PTLB_ID(0x12), STLB_ID(0x3D), FETCH_SIZE(SIZE1), PTLB_DIS, STLB_DIS)
		 STREAM_MATCH_CFG(DIR_READ)
		 STREAM_MATCH_SID_VALUE(0x0)
		 STREAM_MATCH_SID_MASK(0x3FF)>,
		<2 STREAM_CFG(PTLB_ID(0x1), STLB_ID(0x32), FETCH_SIZE(SIZE1), PTLB_EN, STLB_EN)
		 STREAM_MATCH_CFG(DIR_READ)
		 STREAM_MATCH_SID_VALUE(0x80)
		 STREAM_MATCH_SID_MASK(0x3FF)>,
		<3 STREAM_CFG(PTLB_ID(0x2), STLB_ID(0x33), FETCH_SIZE(SIZE1), PTLB_EN, STLB_EN)
		 STREAM_MATCH_CFG(DIR_READ)
		 STREAM_MATCH_SID_VALUE(0x81)
		 STREAM_MATCH_SID_MASK(0x3FF)>,
		<4 STREAM_CFG(PTLB_ID(0x14), STLB_ID(0x41), FETCH_SIZE(SIZE1), PTLB_DIS, STLB_DIS)
		 STREAM_MATCH_CFG(DIR_WRITE)
		 STREAM_MATCH_SID_VALUE(0x100)
		 STREAM_MATCH_SID_MASK(0x3FF)>,
		<5 STREAM_CFG(PTLB_ID(0x3), STLB_ID(0x34), FETCH_SIZE(SIZE1), PTLB_EN, STLB_EN)
		 STREAM_MATCH_CFG(DIR_READ)
		 STREAM_MATCH_SID_VALUE(0x180)
		 STREAM_MATCH_SID_MASK(0x3FF)>,
		<6 STREAM_CFG(PTLB_ID(0x4), STLB_ID(0x35), FETCH_SIZE(SIZE1), PTLB_EN, STLB_EN)
		 STREAM_MATCH_CFG(DIR_READ)
		 STREAM_MATCH_SID_VALUE(0x181)
		 STREAM_MATCH_SID_MASK(0x3FF)>,
		<7 STREAM_CFG(PTLB_ID(0x5), STLB_ID(0x0), FETCH_SIZE(SIZE1), PTLB_DIS, STLB_EN)
		 STREAM_MATCH_CFG(DIR_WRITE)
		 STREAM_MATCH_SID_VALUE(0x180)
		 STREAM_MATCH_SID_MASK(0x3FF)>,
		<8 STREAM_CFG(PTLB_ID(0x6), STLB_ID(0x36), FETCH_SIZE(SIZE1), PTLB_EN, STLB_EN)
		 STREAM_MATCH_CFG(DIR_WRITE)
		 STREAM_MATCH_SID_VALUE(0x181)
		 STREAM_MATCH_SID_MASK(0x3FF)>,
		<9 STREAM_CFG(PTLB_ID(0x7), STLB_ID(0x1), FETCH_SIZE(SIZE1), PTLB_DIS, STLB_EN)
		 STREAM_MATCH_CFG(DIR_WRITE)
		 STREAM_MATCH_SID_VALUE(0x182)
		 STREAM_MATCH_SID_MASK(0x3FF)>,
		<10 STREAM_CFG(PTLB_ID(0x8), STLB_ID(0x37), FETCH_SIZE(SIZE1), PTLB_EN, STLB_EN)
		 STREAM_MATCH_CFG(DIR_WRITE)
		 STREAM_MATCH_SID_VALUE(0x183)
		 STREAM_MATCH_SID_MASK(0x3FF)>,
		<11 STREAM_CFG(PTLB_ID(0x9), STLB_ID(0x6), FETCH_SIZE(SIZE1), PTLB_DIS, STLB_EN)
		 STREAM_MATCH_CFG(DIR_WRITE)
		 STREAM_MATCH_SID_VALUE(0x184)
		 STREAM_MATCH_SID_MASK(0x3FF)>,
		<12 STREAM_CFG(PTLB_ID(0x13), STLB_ID(0x3E), FETCH_SIZE(SIZE1), PTLB_DIS, STLB_DIS)
		 STREAM_MATCH_CFG(DIR_READ)
		 STREAM_MATCH_SID_VALUE(0x200)
		 STREAM_MATCH_SID_MASK(0x3FF)>,
		<13 STREAM_CFG(PTLB_ID(0xA), STLB_ID(0x2), FETCH_SIZE(SIZE1), PTLB_DIS, STLB_EN)
		 STREAM_MATCH_CFG(DIR_WRITE)
		 STREAM_MATCH_SID_VALUE(0x200)
		 STREAM_MATCH_SID_MASK(0x3FF)>,
		<14 STREAM_CFG(PTLB_ID(0xB), STLB_ID(0x38), FETCH_SIZE(SIZE1), PTLB_EN, STLB_EN)
		 STREAM_MATCH_CFG(DIR_WRITE)
		 STREAM_MATCH_SID_VALUE(0x201)
		 STREAM_MATCH_SID_MASK(0x3FF)>,
		<15 STREAM_CFG(PTLB_ID(0xC), STLB_ID(0x3), FETCH_SIZE(SIZE1), PTLB_DIS, STLB_EN)
		 STREAM_MATCH_CFG(DIR_WRITE)
		 STREAM_MATCH_SID_VALUE(0x202)
		 STREAM_MATCH_SID_MASK(0x3FF)>,
		<16 STREAM_CFG(PTLB_ID(0xD), STLB_ID(0x39), FETCH_SIZE(SIZE1), PTLB_EN, STLB_EN)
		 STREAM_MATCH_CFG(DIR_WRITE)
		 STREAM_MATCH_SID_VALUE(0x203)
		 STREAM_MATCH_SID_MASK(0x3FF)>,
		<17 STREAM_CFG(PTLB_ID(0xE), STLB_ID(0x7), FETCH_SIZE(SIZE1), PTLB_DIS, STLB_EN)
		 STREAM_MATCH_CFG(DIR_WRITE)
		 STREAM_MATCH_SID_VALUE(0x204)
		 STREAM_MATCH_SID_MASK(0x3FF)>,
		<18 STREAM_CFG(PTLB_ID(0xF), STLB_ID(0x4), FETCH_SIZE(SIZE1), PTLB_DIS, STLB_EN)
		 STREAM_MATCH_CFG(DIR_WRITE)
		 STREAM_MATCH_SID_VALUE(0x280)
		 STREAM_MATCH_SID_MASK(0x3FF)>,
		<19 STREAM_CFG(PTLB_ID(0x10), STLB_ID(0x5), FETCH_SIZE(SIZE1), PTLB_DIS, STLB_EN)
		 STREAM_MATCH_CFG(DIR_WRITE)
		 STREAM_MATCH_SID_VALUE(0x282)
		 STREAM_MATCH_SID_MASK(0x3FF)>,
		<20 STREAM_CFG(PTLB_ID(0x11), STLB_ID(0x8), FETCH_SIZE(SIZE1), PTLB_DIS, STLB_EN)
		 STREAM_MATCH_CFG(DIR_WRITE)
		 STREAM_MATCH_SID_VALUE(0x284)
		 STREAM_MATCH_SID_MASK(0x3FF)>,
		<21 STREAM_CFG(PTLB_ID(0x15), STLB_ID(0x3A), FETCH_SIZE(SIZE1), PTLB_DIS, STLB_DIS)
		 STREAM_MATCH_CFG(DIR_WRITE)
		 STREAM_MATCH_SID_VALUE(0x300)
		 STREAM_MATCH_SID_MASK(0x3FF)>,
		<22 STREAM_CFG(PTLB_ID(0x16), STLB_ID(0x42), FETCH_SIZE(SIZE1), PTLB_DIS, STLB_DIS)
		 STREAM_MATCH_CFG(DIR_WRITE)
		 STREAM_MATCH_SID_VALUE(0x380)
		 STREAM_MATCH_SID_MASK(0x3FF)>;
	};

	sysmmu_icpu_s0_stream: sysmmu_icpu_s0_stream {
		pmmu0,default_stream =
		<STREAM_CFG(PTLB_ID(0x0), STLB_ID(0x0), FETCH_SIZE(SIZE1), PTLB_DIS, STLB_DIS)>;
		pmmu0,stream_property =
		<1 STREAM_CFG(PTLB_ID(0x1), STLB_ID(0x1), FETCH_SIZE(SIZE1), PTLB_DIS, STLB_DIS)
		 STREAM_MATCH_CFG(DIR_RW)
		 STREAM_MATCH_SID_VALUE(0x1)
		 STREAM_MATCH_SID_MASK(0x1)>;
	};

	sysmmu_m2m_s0_stream: sysmmu_m2m_s0_stream {
		pmmu0,default_stream =
		<STREAM_CFG(PTLB_ID(0x3), STLB_ID(0x13), FETCH_SIZE(SIZE8), PTLB_DIS, STLB_DIS)>;
		pmmu0,stream_property =
		<1 STREAM_CFG(PTLB_ID(0x4), STLB_ID(0x16), FETCH_SIZE(SIZE1), PTLB_EN, STLB_DIS)
		 STREAM_MATCH_CFG(DIR_READ)
		 STREAM_MATCH_SID_VALUE(0x81)
		 STREAM_MATCH_SID_MASK(0x3FF)>,
		<2 STREAM_CFG(PTLB_ID(0x5), STLB_ID(0x6), FETCH_SIZE(SIZE1), PTLB_EN, STLB_EN)
		 STREAM_MATCH_CFG(DIR_WRITE)
		 STREAM_MATCH_SID_VALUE(0x84)
		 STREAM_MATCH_SID_MASK(0x3FF)>,
		<3 STREAM_CFG(PTLB_ID(0x6), STLB_ID(0x7), FETCH_SIZE(SIZE1), PTLB_EN, STLB_EN)
		 STREAM_MATCH_CFG(DIR_WRITE)
		 STREAM_MATCH_SID_VALUE(0x86)
		 STREAM_MATCH_SID_MASK(0x3FF)>,
		<4 STREAM_CFG(PTLB_ID(0x1), STLB_ID(0x12), FETCH_SIZE(SIZE32), PTLB_DIS, STLB_EN)
		 STREAM_MATCH_CFG(DIR_READ)
		 STREAM_MATCH_SID_VALUE(0x80)
		 STREAM_MATCH_SID_MASK(0x3FF)>,
		<5 STREAM_CFG(PTLB_ID(0x1), STLB_ID(0x12), FETCH_SIZE(SIZE32), PTLB_DIS, STLB_EN)
		 STREAM_MATCH_CFG(DIR_WRITE)
		 STREAM_MATCH_SID_VALUE(0x88)
		 STREAM_MATCH_SID_MASK(0x3FF)>,
		<6 STREAM_CFG(PTLB_ID(0x1), STLB_ID(0x12), FETCH_SIZE(SIZE32), PTLB_DIS, STLB_EN)
		 STREAM_MATCH_CFG(DIR_WRITE)
		 STREAM_MATCH_SID_VALUE(0x80)
		 STREAM_MATCH_SID_MASK(0x3FF)>,
		<7 STREAM_CFG(PTLB_ID(0x1), STLB_ID(0x12), FETCH_SIZE(SIZE32), PTLB_DIS, STLB_EN)
		 STREAM_MATCH_CFG(DIR_WRITE)
		 STREAM_MATCH_SID_VALUE(0x82)
		 STREAM_MATCH_SID_MASK(0x3FF)>,
		<8 STREAM_CFG(PTLB_ID(0x9), STLB_ID(0x17), FETCH_SIZE(SIZE1), PTLB_DIS, STLB_DIS)
		 STREAM_MATCH_CFG(DIR_WRITE)
		 STREAM_MATCH_SID_VALUE(0x101)
		 STREAM_MATCH_SID_MASK(0x3FF)>,
		<9 STREAM_CFG(PTLB_ID(0x0), STLB_ID(0x0), FETCH_SIZE(SIZE8), PTLB_EN, STLB_EN)
		 STREAM_MATCH_CFG(DIR_READ)
		 STREAM_MATCH_SID_VALUE(0x180)
		 STREAM_MATCH_SID_MASK(0x3FF)>,
		<10 STREAM_CFG(PTLB_ID(0x7), STLB_ID(0x8), FETCH_SIZE(SIZE1), PTLB_EN, STLB_EN)
		 STREAM_MATCH_CFG(DIR_READ)
		 STREAM_MATCH_SID_VALUE(0x181)
		 STREAM_MATCH_SID_MASK(0x3FF)>,
		<11 STREAM_CFG(PTLB_ID(0x2), STLB_ID(0x3), FETCH_SIZE(SIZE4), PTLB_EN, STLB_EN)
		 STREAM_MATCH_CFG(DIR_WRITE)
		 STREAM_MATCH_SID_VALUE(0x180)
		 STREAM_MATCH_SID_MASK(0x3FF)>,
		<12 STREAM_CFG(PTLB_ID(0x8), STLB_ID(0x9), FETCH_SIZE(SIZE1), PTLB_EN, STLB_EN)
		 STREAM_MATCH_CFG(DIR_WRITE)
		 STREAM_MATCH_SID_VALUE(0x181)
		 STREAM_MATCH_SID_MASK(0x3FF)>,
		<13 STREAM_CFG(PTLB_ID(0xA), STLB_ID(0x18), FETCH_SIZE(SIZE1), PTLB_DIS, STLB_DIS)
		 STREAM_MATCH_CFG(DIR_READ)
		 STREAM_MATCH_SID_VALUE(0x200)
		 STREAM_MATCH_SID_MASK(0x3FF)>;
		pmmu1,default_stream =
		<STREAM_CFG(PTLB_ID(0xE), STLB_ID(0x19), FETCH_SIZE(SIZE1), PTLB_DIS, STLB_DIS)>;
		pmmu1,stream_property =
		<1 STREAM_CFG(PTLB_ID(0x4), STLB_ID(0x14), FETCH_SIZE(SIZE1), PTLB_DIS, STLB_DIS)
		 STREAM_MATCH_CFG(DIR_READ)
		 STREAM_MATCH_SID_VALUE(0x300)
		 STREAM_MATCH_SID_MASK(0x7FF)>,
		<2 STREAM_CFG(PTLB_ID(0x6), STLB_ID(0xA), FETCH_SIZE(SIZE1), PTLB_EN, STLB_EN)
		 STREAM_MATCH_CFG(DIR_READ)
		 STREAM_MATCH_SID_VALUE(0x380)
		 STREAM_MATCH_SID_MASK(0x7FF)>,
		<3 STREAM_CFG(PTLB_ID(0x5), STLB_ID(0x15), FETCH_SIZE(SIZE1), PTLB_DIS, STLB_DIS)
		 STREAM_MATCH_CFG(DIR_WRITE)
		 STREAM_MATCH_SID_VALUE(0x400)
		 STREAM_MATCH_SID_MASK(0x7FF)>,
		<4 STREAM_CFG(PTLB_ID(0x7), STLB_ID(0xB), FETCH_SIZE(SIZE1), PTLB_EN, STLB_EN)
		 STREAM_MATCH_CFG(DIR_WRITE)
		 STREAM_MATCH_SID_VALUE(0x480)
		 STREAM_MATCH_SID_MASK(0x7FF)>,
		<5 STREAM_CFG(PTLB_ID(0x8), STLB_ID(0xC), FETCH_SIZE(SIZE1), PTLB_EN, STLB_EN)
		 STREAM_MATCH_CFG(DIR_WRITE)
		 STREAM_MATCH_SID_VALUE(0x500)
		 STREAM_MATCH_SID_MASK(0x7FF)>,
		<6 STREAM_CFG(PTLB_ID(0x0), STLB_ID(0x1), FETCH_SIZE(SIZE8), PTLB_DIS, STLB_EN)
		 STREAM_MATCH_CFG(DIR_READ)
		 STREAM_MATCH_SID_VALUE(0x580)
		 STREAM_MATCH_SID_MASK(0x7FF)>,
		<7 STREAM_CFG(PTLB_ID(0x9), STLB_ID(0xD), FETCH_SIZE(SIZE1), PTLB_DIS, STLB_EN)
		 STREAM_MATCH_CFG(DIR_READ)
		 STREAM_MATCH_SID_VALUE(0x581)
		 STREAM_MATCH_SID_MASK(0x7FF)>,
		<8 STREAM_CFG(PTLB_ID(0x2), STLB_ID(0x4), FETCH_SIZE(SIZE8), PTLB_DIS, STLB_EN)
		 STREAM_MATCH_CFG(DIR_WRITE)
		 STREAM_MATCH_SID_VALUE(0x580)
		 STREAM_MATCH_SID_MASK(0x7FF)>,
		<9 STREAM_CFG(PTLB_ID(0xA), STLB_ID(0xE), FETCH_SIZE(SIZE1), PTLB_DIS, STLB_EN)
		 STREAM_MATCH_CFG(DIR_WRITE)
		 STREAM_MATCH_SID_VALUE(0x581)
		 STREAM_MATCH_SID_MASK(0x7FF)>,
		<10 STREAM_CFG(PTLB_ID(0x3), STLB_ID(0x5), FETCH_SIZE(SIZE8), PTLB_DIS, STLB_EN)
		 STREAM_MATCH_CFG(DIR_WRITE)
		 STREAM_MATCH_SID_VALUE(0x582)
		 STREAM_MATCH_SID_MASK(0x7FF)>,
		<11 STREAM_CFG(PTLB_ID(0xB), STLB_ID(0xF), FETCH_SIZE(SIZE1), PTLB_DIS, STLB_EN)
		 STREAM_MATCH_CFG(DIR_WRITE)
		 STREAM_MATCH_SID_VALUE(0x583)
		 STREAM_MATCH_SID_MASK(0x7FF)>,
		<12 STREAM_CFG(PTLB_ID(0x1), STLB_ID(0x2), FETCH_SIZE(SIZE8), PTLB_DIS, STLB_EN)
		 STREAM_MATCH_CFG(DIR_READ)
		 STREAM_MATCH_SID_VALUE(0x600)
		 STREAM_MATCH_SID_MASK(0x7FF)>,
		<13 STREAM_CFG(PTLB_ID(0xC), STLB_ID(0x10), FETCH_SIZE(SIZE1), PTLB_DIS, STLB_EN)
		 STREAM_MATCH_CFG(DIR_READ)
		 STREAM_MATCH_SID_VALUE(0x601)
		 STREAM_MATCH_SID_MASK(0x7FF)>,
		<14 STREAM_CFG(PTLB_ID(0xD), STLB_ID(0x11), FETCH_SIZE(SIZE1), PTLB_EN, STLB_EN)
		 STREAM_MATCH_CFG(DIR_WRITE)
		 STREAM_MATCH_SID_VALUE(0x600)
		 STREAM_MATCH_SID_MASK(0x7FF)>,
		<15 STREAM_CFG(PTLB_ID(0xF), STLB_ID(0x1A), FETCH_SIZE(SIZE1), PTLB_DIS, STLB_DIS)
		 STREAM_MATCH_CFG(DIR_READ)
		 STREAM_MATCH_SID_VALUE(0x680)
		 STREAM_MATCH_SID_MASK(0x7FF)>;
	};

	sysmmu_mfc_s0_stream: sysmmu_mfc_s0_stream {
		pmmu0,default_stream =
		<STREAM_CFG(PTLB_ID(0x1), STLB_ID(0x0), FETCH_SIZE(SIZE4), PTLB_DIS, STLB_DIS)>;
		pmmu0,stream_property =
		<1 STREAM_CFG(PTLB_ID(0x0), STLB_ID(0x1), FETCH_SIZE(SIZE4), PTLB_DIS, STLB_EN)
		 STREAM_MATCH_CFG(DIR_RW)
		 STREAM_MATCH_SID_VALUE(0x80)
		 STREAM_MATCH_SID_MASK(0x180)>,
		<2 STREAM_CFG(PTLB_ID(0x2), STLB_ID(0x2), FETCH_SIZE(SIZE1), PTLB_DIS, STLB_DIS)
		 STREAM_MATCH_CFG(DIR_WRITE)
		 STREAM_MATCH_SID_VALUE(0x100)
		 STREAM_MATCH_SID_MASK(0x180)>;
	};

	sysmmu_rgbp_s0_stream: sysmmu_rgbp_s0_stream {
		pmmu0,default_stream =
		<STREAM_CFG(PTLB_ID(0xC), STLB_ID(0x1A), FETCH_SIZE(SIZE1), PTLB_DIS, STLB_DIS)>;
		pmmu0,stream_property =
		<1 STREAM_CFG(PTLB_ID(0x0), STLB_ID(0x4), FETCH_SIZE(SIZE1), PTLB_EN, STLB_EN)
		 STREAM_MATCH_CFG(DIR_WRITE)
		 STREAM_MATCH_SID_VALUE(0x0)
		 STREAM_MATCH_SID_MASK(0x790)>,
		<2 STREAM_CFG(PTLB_ID(0x1), STLB_ID(0x5), FETCH_SIZE(SIZE1), PTLB_EN, STLB_EN)
		 STREAM_MATCH_CFG(DIR_WRITE)
		 STREAM_MATCH_SID_VALUE(0x10)
		 STREAM_MATCH_SID_MASK(0x790)>,
		<3 STREAM_CFG(PTLB_ID(0x2), STLB_ID(0x6), FETCH_SIZE(SIZE1), PTLB_EN, STLB_EN)
		 STREAM_MATCH_CFG(DIR_READ)
		 STREAM_MATCH_SID_VALUE(0x80)
		 STREAM_MATCH_SID_MASK(0x790)>,
		<4 STREAM_CFG(PTLB_ID(0x3), STLB_ID(0x7), FETCH_SIZE(SIZE1), PTLB_EN, STLB_EN)
		 STREAM_MATCH_CFG(DIR_READ)
		 STREAM_MATCH_SID_VALUE(0x100)
		 STREAM_MATCH_SID_MASK(0x790)>,
		<5 STREAM_CFG(PTLB_ID(0x4), STLB_ID(0x8), FETCH_SIZE(SIZE1), PTLB_EN, STLB_EN)
		 STREAM_MATCH_CFG(DIR_WRITE)
		 STREAM_MATCH_SID_VALUE(0x100)
		 STREAM_MATCH_SID_MASK(0x790)>,
		<6 STREAM_CFG(PTLB_ID(0x5), STLB_ID(0x9), FETCH_SIZE(SIZE1), PTLB_EN, STLB_EN)
		 STREAM_MATCH_CFG(DIR_WRITE)
		 STREAM_MATCH_SID_VALUE(0x110)
		 STREAM_MATCH_SID_MASK(0x790)>,
		<7 STREAM_CFG(PTLB_ID(0xD), STLB_ID(0x1C), FETCH_SIZE(SIZE1), PTLB_DIS, STLB_DIS)
		 STREAM_MATCH_CFG(DIR_WRITE)
		 STREAM_MATCH_SID_VALUE(0x200)
		 STREAM_MATCH_SID_MASK(0x790)>,
		<8 STREAM_CFG(PTLB_ID(0xE), STLB_ID(0x1D), FETCH_SIZE(SIZE1), PTLB_DIS, STLB_DIS)
		 STREAM_MATCH_CFG(DIR_WRITE)
		 STREAM_MATCH_SID_VALUE(0x280)
		 STREAM_MATCH_SID_MASK(0x790)>,
		<9 STREAM_CFG(PTLB_ID(0x6), STLB_ID(0xA), FETCH_SIZE(SIZE1), PTLB_EN, STLB_EN)
		 STREAM_MATCH_CFG(DIR_READ)
		 STREAM_MATCH_SID_VALUE(0x380)
		 STREAM_MATCH_SID_MASK(0x790)>,
		<10 STREAM_CFG(PTLB_ID(0x7), STLB_ID(0xB), FETCH_SIZE(SIZE1), PTLB_EN, STLB_EN)
		 STREAM_MATCH_CFG(DIR_READ)
		 STREAM_MATCH_SID_VALUE(0x390)
		 STREAM_MATCH_SID_MASK(0x790)>,
		<11 STREAM_CFG(PTLB_ID(0x8), STLB_ID(0xC), FETCH_SIZE(SIZE1), PTLB_EN, STLB_EN)
		 STREAM_MATCH_CFG(DIR_READ)
		 STREAM_MATCH_SID_VALUE(0x400)
		 STREAM_MATCH_SID_MASK(0x790)>,
		<12 STREAM_CFG(PTLB_ID(0x9), STLB_ID(0xD), FETCH_SIZE(SIZE1), PTLB_EN, STLB_EN)
		 STREAM_MATCH_CFG(DIR_READ)
		 STREAM_MATCH_SID_VALUE(0x410)
		 STREAM_MATCH_SID_MASK(0x790)>,
		<13 STREAM_CFG(PTLB_ID(0xA), STLB_ID(0xE), FETCH_SIZE(SIZE1), PTLB_EN, STLB_EN)
		 STREAM_MATCH_CFG(DIR_READ)
		 STREAM_MATCH_SID_VALUE(0x480)
		 STREAM_MATCH_SID_MASK(0x790)>,
		<14 STREAM_CFG(PTLB_ID(0xB), STLB_ID(0xF), FETCH_SIZE(SIZE1), PTLB_EN, STLB_EN)
		 STREAM_MATCH_CFG(DIR_READ)
		 STREAM_MATCH_SID_VALUE(0x680)
		 STREAM_MATCH_SID_MASK(0x790)>;
		pmmu1,default_stream =
		<STREAM_CFG(PTLB_ID(0x1), STLB_ID(0x10), FETCH_SIZE(SIZE1), PTLB_EN, STLB_EN)>;
		pmmu1,stream_property =
		<1 STREAM_CFG(PTLB_ID(0x2), STLB_ID(0x11), FETCH_SIZE(SIZE1), PTLB_EN, STLB_EN)
		 STREAM_MATCH_CFG(DIR_WRITE)
		 STREAM_MATCH_SID_VALUE(0x184)
		 STREAM_MATCH_SID_MASK(0xF84)>,
		<2 STREAM_CFG(PTLB_ID(0x0), STLB_ID(0x18), FETCH_SIZE(SIZE32), PTLB_EN, STLB_EN)
		 STREAM_MATCH_CFG(DIR_READ)
		 STREAM_MATCH_SID_VALUE(0x700)
		 STREAM_MATCH_SID_MASK(0xF84)>,
		<3 STREAM_CFG(PTLB_ID(0x3), STLB_ID(0x1), FETCH_SIZE(SIZE1), PTLB_EN, STLB_EN)
		 STREAM_MATCH_CFG(DIR_READ)
		 STREAM_MATCH_SID_VALUE(0x704)
		 STREAM_MATCH_SID_MASK(0xF84)>,
		<4 STREAM_CFG(PTLB_ID(0x4), STLB_ID(0x12), FETCH_SIZE(SIZE1), PTLB_EN, STLB_EN)
		 STREAM_MATCH_CFG(DIR_WRITE)
		 STREAM_MATCH_SID_VALUE(0x780)
		 STREAM_MATCH_SID_MASK(0xF84)>,
		<5 STREAM_CFG(PTLB_ID(0x5), STLB_ID(0x13), FETCH_SIZE(SIZE1), PTLB_EN, STLB_EN)
		 STREAM_MATCH_CFG(DIR_WRITE)
		 STREAM_MATCH_SID_VALUE(0x784)
		 STREAM_MATCH_SID_MASK(0xF84)>,
		<6 STREAM_CFG(PTLB_ID(0x6), STLB_ID(0x14), FETCH_SIZE(SIZE1), PTLB_EN, STLB_EN)
		 STREAM_MATCH_CFG(DIR_WRITE)
		 STREAM_MATCH_SID_VALUE(0x800)
		 STREAM_MATCH_SID_MASK(0xF84)>;
		pmmu2,default_stream =
		<STREAM_CFG(PTLB_ID(0x1), STLB_ID(0x15), FETCH_SIZE(SIZE1), PTLB_EN, STLB_EN)>;
		pmmu2,stream_property =
		<1 STREAM_CFG(PTLB_ID(0x2), STLB_ID(0x16), FETCH_SIZE(SIZE1), PTLB_EN, STLB_EN)
		 STREAM_MATCH_CFG(DIR_WRITE)
		 STREAM_MATCH_SID_VALUE(0x900)
		 STREAM_MATCH_SID_MASK(0xF84)>,
		<2 STREAM_CFG(PTLB_ID(0x3), STLB_ID(0x17), FETCH_SIZE(SIZE1), PTLB_EN, STLB_EN)
		 STREAM_MATCH_CFG(DIR_WRITE)
		 STREAM_MATCH_SID_VALUE(0x904)
		 STREAM_MATCH_SID_MASK(0xF84)>,
		<3 STREAM_CFG(PTLB_ID(0x0), STLB_ID(0x0), FETCH_SIZE(SIZE16), PTLB_EN, STLB_EN)
		 STREAM_MATCH_CFG(DIR_READ)
		 STREAM_MATCH_SID_VALUE(0x880)
		 STREAM_MATCH_SID_MASK(0xF84)>;
		pmmu3,default_stream =
		<STREAM_CFG(PTLB_ID(0x3), STLB_ID(0x1B), FETCH_SIZE(SIZE1), PTLB_DIS, STLB_DIS)>;
		pmmu3,stream_property =
		<1 STREAM_CFG(PTLB_ID(0x1), STLB_ID(0x2), FETCH_SIZE(SIZE1), PTLB_EN, STLB_EN)
		 STREAM_MATCH_CFG(DIR_READ)
		 STREAM_MATCH_SID_VALUE(0xA80)
		 STREAM_MATCH_SID_MASK(0xF84)>,
		<2 STREAM_CFG(PTLB_ID(0x0), STLB_ID(0x19), FETCH_SIZE(SIZE32), PTLB_EN, STLB_EN)
		 STREAM_MATCH_CFG(DIR_READ)
		 STREAM_MATCH_SID_VALUE(0xA00)
		 STREAM_MATCH_SID_MASK(0xF84)>,
		<3 STREAM_CFG(PTLB_ID(0x2), STLB_ID(0x3), FETCH_SIZE(SIZE1), PTLB_EN, STLB_EN)
		 STREAM_MATCH_CFG(DIR_READ)
		 STREAM_MATCH_SID_VALUE(0xA04)
		 STREAM_MATCH_SID_MASK(0xF84)>;
	};

	sysmmu_yuvp_s0_stream: sysmmu_yuvp_s0_stream {
		pmmu0,default_stream =
		<STREAM_CFG(PTLB_ID(0x5), STLB_ID(0x8), FETCH_SIZE(SIZE1), PTLB_DIS, STLB_DIS)>;
		pmmu0,stream_property =
		<1 STREAM_CFG(PTLB_ID(0x8), STLB_ID(0x2), FETCH_SIZE(SIZE1), PTLB_DIS, STLB_DIS)
		 STREAM_MATCH_CFG(DIR_WRITE)
		 STREAM_MATCH_SID_VALUE(0x0)
		 STREAM_MATCH_SID_MASK(0x3FF)>,
		<2 STREAM_CFG(PTLB_ID(0x0), STLB_ID(0x3), FETCH_SIZE(SIZE1), PTLB_EN, STLB_EN)
		 STREAM_MATCH_CFG(DIR_READ)
		 STREAM_MATCH_SID_VALUE(0x80)
		 STREAM_MATCH_SID_MASK(0x3FF)>,
		<3 STREAM_CFG(PTLB_ID(0x1), STLB_ID(0x4), FETCH_SIZE(SIZE1), PTLB_EN, STLB_EN)
		 STREAM_MATCH_CFG(DIR_READ)
		 STREAM_MATCH_SID_VALUE(0x100)
		 STREAM_MATCH_SID_MASK(0x3FF)>,
		<4 STREAM_CFG(PTLB_ID(0x2), STLB_ID(0x5), FETCH_SIZE(SIZE1), PTLB_EN, STLB_EN)
		 STREAM_MATCH_CFG(DIR_READ)
		 STREAM_MATCH_SID_VALUE(0x180)
		 STREAM_MATCH_SID_MASK(0x3FF)>,
		<5 STREAM_CFG(PTLB_ID(0x3), STLB_ID(0x6), FETCH_SIZE(SIZE1), PTLB_EN, STLB_EN)
		 STREAM_MATCH_CFG(DIR_READ)
		 STREAM_MATCH_SID_VALUE(0x200)
		 STREAM_MATCH_SID_MASK(0x3FF)>,
		<6 STREAM_CFG(PTLB_ID(0x4), STLB_ID(0x7), FETCH_SIZE(SIZE1), PTLB_EN, STLB_EN)
		 STREAM_MATCH_CFG(DIR_READ)
		 STREAM_MATCH_SID_VALUE(0x280)
		 STREAM_MATCH_SID_MASK(0x3FF)>,
		<7 STREAM_CFG(PTLB_ID(0x6), STLB_ID(0x0), FETCH_SIZE(SIZE16), PTLB_DIS, STLB_DIS)
		 STREAM_MATCH_CFG(DIR_WRITE)
		 STREAM_MATCH_SID_VALUE(0x300)
		 STREAM_MATCH_SID_MASK(0x3FF)>,
		<8 STREAM_CFG(PTLB_ID(0x7), STLB_ID(0x1), FETCH_SIZE(SIZE16), PTLB_DIS, STLB_DIS)
		 STREAM_MATCH_CFG(DIR_READ)
		 STREAM_MATCH_SID_VALUE(0x300)
		 STREAM_MATCH_SID_MASK(0x3FF)>;
	};

};
